# TC37XPD register map
Vendor: Infineon; Series: ATVMC; File version: 100
CPU: other r0p0, little endian, MPU, FPU, vendor SysTick, 4 interrupt priority bits
Registers are 32-bit, read-write, reset 0x0 unless marked. A register's access mark holds for its fields unless they carry their own. Offsets are from the block's base; [hi:lo] are bit positions; lines under a group give offsets from that group; {n}, {i} and the like mark numbered series.

## MTU
Base 0xF0060000
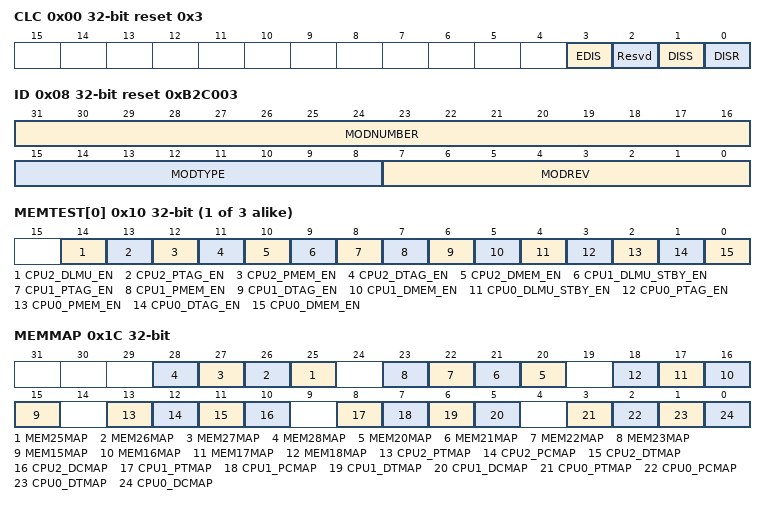
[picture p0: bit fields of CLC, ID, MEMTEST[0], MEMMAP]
0x00 CLC access per field reset 0x3 — Clock Control Register resetvalue={Application Reset:0x3}
  [3] EDIS rw — Sleep Mode Enable Control EDIS. Used for module Sleep Mode control. While any bit of tcu mbist en i x is asserted sleep mode is ignored and the MTU kernel clock runs until all tcu mbist en i x bits are deasserted.
  [2] Resvd ro — Resvd Resvd. Read as 0. Must be written with 0 H
  [1] DISS ro — Module Disable Status Bit DISS. Bit indicates the current status of the module If the RMC field is implemented and if it is 0 DISS is set automatically.
  [0] DISR rw — Module Disable Request Bit DISR. Used for enable disable control of the module. While any bit of tcu mbist en i x is asserted CLC.DISR is ignored and the MTU kernel clock runs until all tcu mbist en i x bits are deasserted.
0x08 ID ro reset 0xB2C003 — Identification Register resetvalue={Application Reset:0x0B2C003}
  [31:16] MODNUMBER — Module Number MODNUMBER. This bit field defines the module identification number. The idenfication number for the AurixPlus Platform MTU module is 00B2 H
  [15:8] MODTYPE — Module Type MODTYPE. This bit field is C0 H . It defines a 32 bit module
  [7:0] MODREV — Module Revision Number MODREV. This bit field indicates the revision number of the MTU module provided by design team .
{0x10+4i} MEMTEST[{i}] (i=0..2) — Memory MBIST Enable Register 0 resetvalue={Application Reset:0x0}
  [14] CPU2_DLMU_EN — CPU2 DLMU memory SSH instance Enable CPU2 DLMU EN
  [13] CPU2_PTAG_EN — CPU2 PTAG SSH instance Enable CPU2 PTAG EN
  [12] CPU2_PMEM_EN — CPU2 PMEM SSH instance Enable CPU2 PMEM EN
  [11] CPU2_DTAG_EN — CPU2 DTAG SSH instance Enable CPU2 DTAG EN
  [10] CPU2_DMEM_EN — CPU2 DMEM SSH instance Enable CPU2 DMEM EN
  [9] CPU1_DLMU_STBY_EN — CPU1 STANDBY DLMU SSH instance Enable CPU1 DLMU STBY EN
  [8] CPU1_PTAG_EN — CPU1 PTAG SSH instance Enable CPU1 PTAG EN
  [7] CPU1_PMEM_EN — CPU1 PMEM SSH instance Enable CPU1 PMEM EN
  [6] CPU1_DTAG_EN — CPU1 DTAG SSH instance Enable CPU1 DTAG EN
  [5] CPU1_DMEM_EN — CPU1 DMEM SSH instance Enable CPU1 DMEM EN
  [4] CPU0_DLMU_STBY_EN — CPU0 STANDBY DLMU SSH instance Enable CPU0 DLMU STBY EN
  [3] CPU0_PTAG_EN — CPU0 PTAG SSH instance Enable CPU0 PTAG EN
  [2] CPU0_PMEM_EN — CPU0 PMEM SSH instance Enable CPU0 PMEM EN
  [1] CPU0_DTAG_EN — CPU0 DTAG SSH instance Enable CPU0 DTAG EN
  [0] CPU0_DMEM_EN — CPU0 DMEM SSH instance Enable CPU0 DMEM EN
0x1C MEMMAP access per field — Memory Mapping Enable Register resetvalue={Application Reset:0x0}
  [n] MEM{n}MAP ro (n=25..28) — MEM31 Mapping Enable MEM31MAP. Reserved Not used in this product. Shall be written with zero.
  [n] MEM{n}MAP ro (n=20..23) — MEM31 Mapping Enable MEM31MAP. Reserved Not used in this product. Shall be written with zero.
  [n] MEM{n}MAP ro (n=15..18) — MEM31 Mapping Enable MEM31MAP. Reserved Not used in this product. Shall be written with zero.
  [13] CPU2_PTMAP ro — CPU2 PTAG Mapping CPU2 PTMAP. Read only. Mirrors the state of CPU2 PCMAP. CPU P cache memories may only be mapped simultaneously.
  [12] CPU2_PCMAP rw — CPU2 PCACHE Mapping CPU2 PCMAP
  [11] CPU2_DTMAP ro — CPU2 DTAG Mapping CPU2 DTMAP. Read only. Mirrors the state of CPU2 DCMAP. CPU D cache memories may only be mapped simultaneously.
  [10] CPU2_DCMAP rw — CPU2 DCache Mapping CPU2 DCMAP
  [8] CPU1_PTMAP ro — CPU1 PTAG Mapping CPU1 PTMAP. Read only. Mirrors the state of CPU1 PCMAP. CPU P cache memories may only be mapped simultaneously.
  [7] CPU1_PCMAP rw — CPU1 PCACHE Mapping CPU1 PCMAP
  [6] CPU1_DTMAP ro — CPU1 DTAG Mapping CPU1 DTMAP. Read only. Mirrors the state of CPU1 DCMAP. CPU D cache memories may only be mapped simultaneously.
  [5] CPU1_DCMAP rw — CPU1 DCache Mapping CPU1 DCMAP
  [3] CPU0_PTMAP ro — CPU0 PTAG Mapping CPU0 PTMAP. Read only. Mirrors the state of CPU0 PCMAP. CPU P cache memories may only be mapped simultaneously.
  [2] CPU0_PCMAP rw — CPU0 PCACHE Mapping CPU0 PCMAP
  [1] CPU0_DTMAP ro — CPU0 DTAG Mapping CPU0 DTMAP. Read only. Mirrors the state of CPU0 DCMAP. CPU D cache memories may only be mapped simultaneously.
  [0] CPU0_DCMAP rw — CPU0 DCache Mapping CPU0 DCMAP
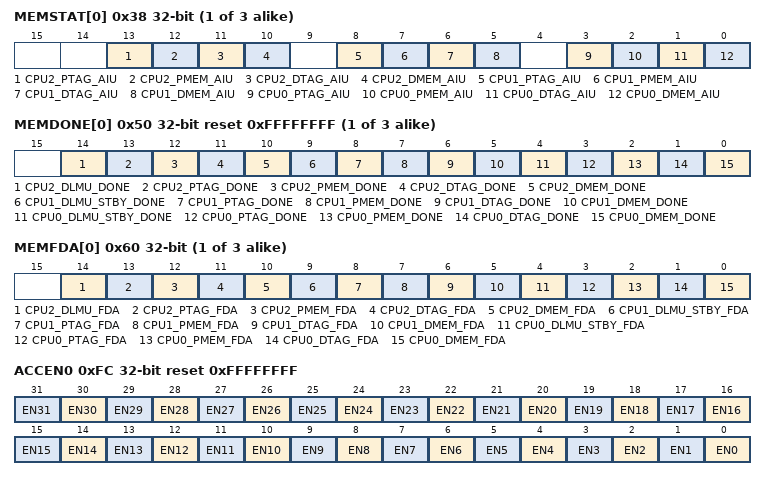
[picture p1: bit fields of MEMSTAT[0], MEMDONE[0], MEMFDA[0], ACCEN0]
{0x38+4i} MEMSTAT[{i}] (i=0..2) ro — Memory Status Register 0 resetvalue={Application Reset:0x0}
  [13] CPU2_PTAG_AIU — CPU2 PTAG MBIST AutoInitialize Underway CPU2 PTAG AIU. This bit indicates whether an automatic data initialization has been triggered by a change of state of MEMTEST.MEMxEN or MEMxMAP but that the intialization sequence has not yet completed.
  [12] CPU2_PMEM_AIU — CPU2 PMEM Partial AutoInitialize of Cache Partition Underway CPU2 PMEM AIU. This bit indicates whether an automatic data initialization has been triggered by a change of state of MEMTEST.MEMxEN or MEMxMAP but that the intialization sequence has not yet completed.
  [11] CPU2_DTAG_AIU — CPU2 DTAG MBIST AutoInitialize Underway CPU2 DTAG AIU. This bit indicates whether an automatic data initialization has been triggered by a change of state of MEMTEST.MEMxEN or MEMxMAP but that the intialization sequence has not yet completed.
  [10] CPU2_DMEM_AIU — CPU2 DMEM Partial AutoInitialize of Cache Partition Underway CPU2 DMEM AIU. This bit indicates whether an automatic data initialization has been triggered by a change of state of MEMTEST.MEMxEN or MEMxMAP but that the intialization sequence has not yet completed.
  [8] CPU1_PTAG_AIU — CPU1 PTAG MBIST AutoInitialize Underway CPU1 PTAG AIU. This bit indicates whether an automatic data initialization has been triggered by a change of state of MEMTEST.MEMxEN or MEMxMAP but that the intialization sequence has not yet completed.
  [7] CPU1_PMEM_AIU — CPU1 PMEM Partial AutoInitialize of Cache Partition Underway CPU1 PMEM AIU. This bit indicates whether an automatic data initialization has been triggered by a change of state of MEMTEST.MEMxEN or MEMxMAP but that the intialization sequence has not yet completed.
  [6] CPU1_DTAG_AIU — CPU1 DTAG MBIST AutoInitialize Underway CPU1 DTAG AIU. This bit indicates whether an automatic data initialization has been triggered by a change of state of MEMTEST.MEMxEN or MEMxMAP but that the intialization sequence has not yet completed.
  [5] CPU1_DMEM_AIU — CPU1 DMEM Partial AutoInitialize of Cache Partition Underway CPU1 DMEM AIU. This bit indicates whether an automatic data initialization has been triggered by a change of state of MEMTEST.MEMxEN or MEMxMAP but that the intialization sequence has not yet completed.
  [3] CPU0_PTAG_AIU — CPU0 PTAG MBIST AutoInitialize Underway CPU0 PTAG AIU. This bit indicates whether an automatic data initialization has been triggered by a change of state of MEMTEST.MEMxEN or MEMxMAP but that the intialization sequence has not yet completed.
  [2] CPU0_PMEM_AIU — CPU0 PMEM Partial AutoInitialize of Cache Partition Underway CPU0 PMEM AIU. This bit indicates whether an automatic data initialization has been triggered by a change of state of MEMTEST.MEMxEN or MEMxMAP but that the intialization sequence has not yet completed.
  [1] CPU0_DTAG_AIU — CPU0 DTAG MBIST AutoInitialize Underway CPU0 DTAG AIU. This bit indicates whether an automatic data initialization has been triggered by a change of state of MEMTEST.MEMxEN or MEMxMAP but that the intialization sequence has not yet completed.
  [0] CPU0_DMEM_AIU — CPU0 DMEM Partial AutoInitialize of Cache Partition Underway CPU0 DMEM AIU. This bit indicates whether an automatic data initialization has been triggered by a change of state of MEMTEST.MEMxEN or MEMxMAP but that the intialization sequence has not yet completed.
{0x50+4i} MEMDONE[{i}] (i=0..2) ro reset 0xFFFFFFFF — Memory Test Done Status Register 0 resetvalue={Application Reset:0x0FFFFFFFF}
  [14] CPU2_DLMU_DONE — CPU2 DLMU memory Test Done Status CPU2 DLMU DONE
  [13] CPU2_PTAG_DONE — CPU2 PTAG Test Done Status CPU2 PTAG DONE
  [12] CPU2_PMEM_DONE — CPU2 PMEM Test Done Status CPU2 PMEM DONE
  [11] CPU2_DTAG_DONE — CPU2 DTAG Test Done Status CPU2 DTAG DONE
  [10] CPU2_DMEM_DONE — CPU2 DMEM Test Done Status CPU2 DMEM DONE
  [9] CPU1_DLMU_STBY_DONE — CPU1 STANDBY DLMU Test Done Status CPU1 DLMU STBY DONE
  [8] CPU1_PTAG_DONE — CPU1 PTAG Test Done Status CPU1 PTAG DONE
  [7] CPU1_PMEM_DONE — CPU1 PMEM Test Done Status CPU1 PMEM DONE
  [6] CPU1_DTAG_DONE — CPU1 DTAG Test Done Status CPU1 DTAG DONE
  [5] CPU1_DMEM_DONE — CPU1 DMEM Test Done Status CPU1 DMEM DONE
  [4] CPU0_DLMU_STBY_DONE — CPU0 STANDBY DLMU Test Done Status CPU0 DLMU STBY DONE
  [3] CPU0_PTAG_DONE — CPU0 PTAG Test Done Status CPU0 PTAG DONE
  [2] CPU0_PMEM_DONE — CPU0 PMEM Test Done Status CPU0 PMEM DONE
  [1] CPU0_DTAG_DONE — CPU0 DTAG Test Done Status CPU0 DTAG DONE
  [0] CPU0_DMEM_DONE — CPU0 DMEM Test Done Status CPU0 DMEM DONE
{0x60+4i} MEMFDA[{i}] (i=0..2) ro — Memory Test FDA Status Register 0 resetvalue={Application Reset:0x0}
  [14] CPU2_DLMU_FDA — CPU2 DLMU memory Test FDA Status CPU2 DLMU FDA
  [13] CPU2_PTAG_FDA — CPU2 PTAG Test FDA Status CPU2 PTAG FDA
  [12] CPU2_PMEM_FDA — CPU2 PMEM Test FDA Status CPU2 PMEM FDA
  [11] CPU2_DTAG_FDA — CPU2 DTAG Test FDA Status CPU2 DTAG FDA
  [10] CPU2_DMEM_FDA — CPU2 DMEM Test FDA Status CPU2 DMEM FDA
  [9] CPU1_DLMU_STBY_FDA — CPU1 STANDBY DLMU Test FDA Status CPU1 DLMU STBY FDA
  [8] CPU1_PTAG_FDA — CPU1 PTAG Test FDA Status CPU1 PTAG FDA
  [7] CPU1_PMEM_FDA — CPU1 PMEM Test FDA Status CPU1 PMEM FDA
  [6] CPU1_DTAG_FDA — CPU1 DTAG Test FDA Status CPU1 DTAG FDA
  [5] CPU1_DMEM_FDA — CPU1 DMEM Test FDA Status CPU1 DMEM FDA
  [4] CPU0_DLMU_STBY_FDA — CPU0 STANDBY DLMU Test FDA Status CPU0 DLMU STBY FDA
  [3] CPU0_PTAG_FDA — CPU0 PTAG Test FDA Status CPU0 PTAG FDA
  [2] CPU0_PMEM_FDA — CPU0 PMEM Test FDA Status CPU0 PMEM FDA
  [1] CPU0_DTAG_FDA — CPU0 DTAG Test FDA Status CPU0 DTAG FDA
  [0] CPU0_DMEM_FDA — CPU0 DMEM Test FDA Status CPU0 DMEM FDA
0xFC ACCEN0 reset 0xFFFFFFFF — Access Enable Register 0 resetvalue={Application Reset:0x0FFFFFFFF}
  [n] EN{n} (n=0..31) — Access Enable for Master TAG ID 31 EN31. This bit enables write access to the MTU kernel addresses for transactions with the Master TAG ID n
{0x1000+0x100*i} MC[{i}] (i=0..95) group
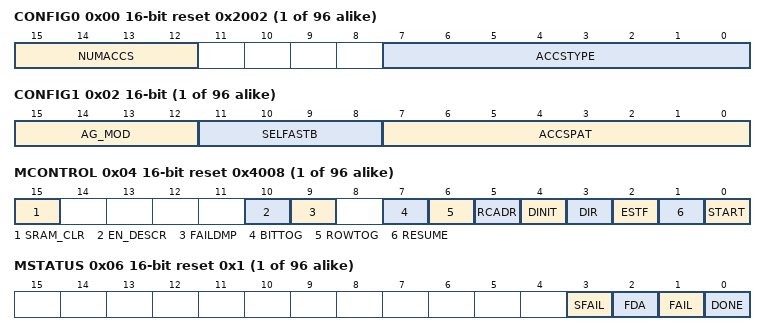
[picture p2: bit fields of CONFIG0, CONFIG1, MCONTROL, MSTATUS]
  0x00 CONFIG0 16-bit reset 0x2002 — Configuration Registers resetvalue={Application Reset:0x2002}
    [15:12] NUMACCS — Number of accesses per address NUMACCS. This field specifies the total number of accesses which are being performed to each single address in the current marching element. Allowed values 0 8 Due to size limitation of CONFIG0.ACCSTYPE and CONFIG1.ACCSPAT fields . If NUMACCS 0 will not access a memory. If NUMACCS gt 8 8 accesses will be performed.
    [7:0] ACCSTYPE — Access type ACCSTYPE. This field specifies the type of access which is being performed to each single address in the current marching element. ACCSTYPE n specifies the n th access of the marching element. 0 b write access 1 b read access
  0x02 CONFIG1 16-bit — Configuration Register 1 resetvalue={Application Reset:0x0}
    [15:12] AG_MOD — Address Generator Mode AG MOD. These bits enable the special hardware for performing the more complex addressing schemes. In case RANGE.RAEN range enable is set to 0 single access linear address mode has to be selected and NUMACCS set to 1.
    [11:8] SELFASTB — Select Fast Bit SELFASTB. This field defines during a 2 i test the address bit position that has the Hamming distance of 1 i. e. changes fastest. Bit 0 of either column or row address is swapped with the indicated bit of either column or row according to MCONTROL.RCADR. MCONTROL.RCADR 0 gt column MCONTROL.RCADR 1 gt row
    [7:0] ACCSPAT — Access pattern ACCSPAT. When AG MOD is selected for any test other than the Non Destructive test this field specifies directly the bit pattern i.e. 0 or 1 which is being used for an access to each single address in the current marching element. ACCSPAT n specifies the n th access of the marching element. These patterns are toggled according to MCONTROL.BITTOG and MCONTROL.ROWTOG. When AG MOD selects the Non Destructive test For corresponding ACCSTYPE as READ or WRITE access Program 0 when the previous read access was with normal data and 1 when the previous read was with inverted data. Note When considering the previous read access consider that the last access is a previous access to the first as a wrap around . Please refer to section on Non Destructive test for more details on how to program these bits.
  0x04 MCONTROL 16-bit reset 0x4008 — MBIST Control Register resetvalue={Application Reset:0x4008}
    [15] SRAM_CLR — Clear the SRAM SRAM CLR. This bit initializes the complete SRAM with ECC correct All 0 data. Execution is started with MCONTROL.START. For this predefined action any information contained in CONFIG0 1 RANGE registers and the bits BITTOG ROWTOG and DIR are ignored. This bit shall not be set together with other initialization or test configurations. After the SRAM clearing is complete the software has to reset this bit back to 0 before disabling the SSH. From a normal application it is forbidden to set this bit together with other initialization features. However in case it happens then this bit has lower priority than auto data init or partial erase triggered via MTU socket signals but higher priority than initialization triggered by MCONTROL.DINIT and the effect will be always that of executing the higher priority alone.
    [10] EN_DESCR — Enable Descrambling. This bit has an effect only when the SSH itself is enabled. If this bit is set the internal address de scrambler in the SSH will be enabled. That is if this bit is set the logical addresses generated from the SSH state machine and given to the SRAM input are translated to physical addresses. The reset value is 0 hence the de scrambler is not enabled by default i.e. by default the logical addresses are not translated to physical .
    [9] FAILDMP — Fail bitmap dump FAILDMP. This field enables a dump of the failing address and a fail bit map after a fault has been detected. The memory test is suspended afterwards and resumed by MCONTROL.RESUME. MSTATUS.FDA shows that a fail dump is available. This functionality can be used only if bit MCONTROL.LDRED xa0 1. In case a fail dump is available RDBFL will contain the fail bit map and ETRR the failing address.
    [7] BITTOG — Bit toggling BITTOG. This field specifies whether to toggle the used bit pattern non inverted inverted with each physical memory column. This is required when writing a checkerboard pattern or a column stripe pattern. For GALPAT this bit has to be 0.
    [6] ROWTOG — Row toggling ROWTOG. This field specifies whether to toggle the used bit pattern non inverted inverted with each physical memory row. This is required when writing a checkerboard pattern or a row stripe pattern. For GALPAT this bit has to be 0.
    [5] RCADR — Fast Row Fast Column Addressing Scheme Select RCADR. This bit selects between fast row and fast column addressing. 8220 Fast Row 8221 moves along the word lines first and then in bit line direction 8220 Fast Column 8221 along the bit lines first.
    [4] DINIT — Data Initialization Enable DINIT. This bit enables a write of the RDBFL data to all locations defined by the range register. RDBFL can contain data that will produce an ECC error. Execution is started with MCONTROL.START. For this predefined action any information contained in CONFIG0 1 registers and the bits BITTOG ROWTOG and DIR are ignored.
    [3] DIR — Direction Select DIR. This field specifies the direction of a memory test operation.
    [2] ESTF — Enable Sticky Fail Bit ESTF. This bit enables the sticky fail bit MSTATUS.SFAIL. If set any fails will be collected in MSTATUS.SFAIL. Resetting this bit to 0 will also reset MSTATUS.SFAIL.
    [1] RESUME — Resume failed test RESUME. This bit allows a test with fail that got suspended to be resumed after the dump of the fail bit map. A restart is possible only if MSTATUS.FDA was reset by hardware. It will be reset by hardware once the test is resumed.
    [0] START — START START. If this bit is written to 160 8217 1 8217 by software the memory test will start. If it is reset by software and the test has finished MSTATUS.DONE will be set to 1. If MCONTROL.FAILDMP is set a fail will stop the current execution. RESUME will continue a suspended test.
  0x06 MSTATUS 16-bit ro reset 0x1 — Status Register resetvalue={Application Reset:0x1}
    [3] SFAIL — Sticky Fail Bit SFAIL. This bit is set to 1 together with MSTATUS.FAIL provided MCONTROL.ESTF is set. In contrast to FAIL it will not be reset when a new test is started. Therefore it will collect fail information over more than one MBIST run. It will be reset when MCONTROL.ESTF is reset or MBIST mode is switched off.
    [2] FDA — Fail Dump Available FDA. This bit shows that a fail has occurred if MCONTROL.FAILDMP is set. The test is suspended and fail dump information is available. The fail bit map is in RDBFL and the associated address is in ETRR 0 . As long as no fail has occurred RDBFL contains the last read information and ETRR has no valid data . This bit will be set by hardware. It will be reset when MSTATUS was read with MSTATUS.FDA 1 and the dump information was read from ETRR and RDBFL. Only the last read from the last word of RDBFL is checked by the hardware and taken as an indication for a complete read. A suspended test will be resumed by MCONTROL.RESUME if FDA was reset. This forms some sort of handshake to insure that a suspended test can only be resumed by a broadcasted MCONTROL.RESUME if the last fail information was actually collected.
    [1] FAIL — FAIL FAIL. This bit will be reset when a test is being started. It will be set to 8216 1 8217 by hardware under the following conditions a when performing a test without redundancy MCONTROL.LDRED 8217 0 8217 and MCONTROL.USERED 8217 0 8217 FAIL 8217 1 8217 if the memory has at least one fault. Here fault includes any error in the data as well as an address error when enabled via ALMSRCS.ADDRE. In this case an application reset has to be issued to clear the FAIL bit. b when performing a test with dynamic update of redundancy MCONTROL.LDRED 8217 1 8217 and MCONTROL.USERED 8217 0 8217 FAIL 8217 1 8217 if the number of memory faults exceeds the number of redundant cells. In this case an application reset has to be performed to clear the FAIL bit. c when performing a test with pre configured redundancy MCONTROL.USERED 8217 1 8217 FAIL 8217 1 8217 if the memory or redundancy has at least one fault
    [0] DONE — DONE DONE. This bit is reset at the start of a test and set when a test is completed and MCONTROL.START was reset by software. It is not set when a test is interrupted for fail dump.
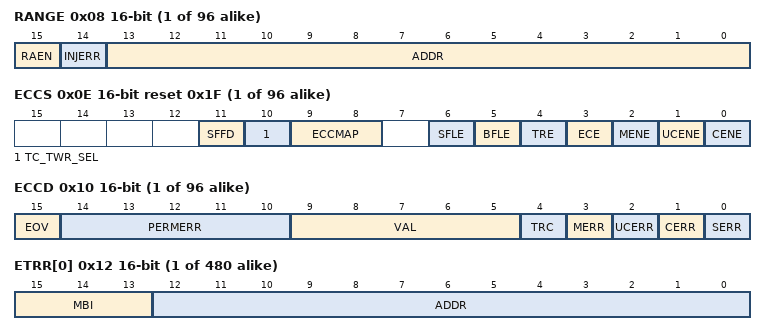
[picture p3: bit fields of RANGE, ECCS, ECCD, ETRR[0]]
  0x08 RANGE 16-bit reset not defined — Range Register single address mode resetvalue={Application Reset:0x0}
    [15] RAEN — Range Enable RAEN. 0 Disabled single address mode. In this case a single word can be addressed for read or write. Config registers have to be set as follows CONFIG.NUMACCS 8220 0001 8221 single access CONFIG.AG MOD 8220 0000 8221 linear MCONTROL.DIR 1 up For read just the value in this location will be delivered. No check against expected values is made i.e. MSTATUS.FAIL will not be set. 1 Enabled. ADDR 13 7 is interpreted as Upper Range Limit. ADDR 6 0 is interpreted as Lower Range Limit.
    [14] INJERR — Inject Error INJERR. Enables Error Injection during march tests. This is supported only for linear march tests.
    [13:0] ADDR — Address ADDR. When RAEN 0 This field specifies the address of a single memory location. Reads and writes to this location are possible. When RAEN 1 this field is interpreted as 2 different fields. ADDR 13 7 is interpreted as Upper Range Limit. ADDR 6 0 is interpreted as Lower Range Limit. For smaller SRAMs which require lesser number of address bits the MSB bits are reserved. Writes to these bits are ignored and reads return 8216 0 8217 .
  0x0C REVID 16-bit ro reset 0x610 — Revision ID Register resetvalue={Application Reset:0x610}
    [15:0] REV_ID — Revision Identifier REV ID. This field defines the currently implemented release version and functionality of the used MBIST ECC controller to track the MBIST ECC version for easier handling at the tester.
  0x0E ECCS 16-bit reset 0x1F — ECC Safety Register resetvalue={Application Reset:0x1F}
    [11] SFFD — Safety Flip Flop Diagnostics SFFD. Safety Flip Flop Diagnostics bit. Setting this bit triggers a Safety Flip Flop self test. The result of the test i.e. any error status in the safety FFs can be obtained from the OPERR or MISCERR bits in the FAULTSTS register.
    [10] TC_TWR_SEL — TriCore Tower Select TC TWR SEL. For TriCore PMEM only. This bit selects a cache way to run the non destructive inversion test on. This bit represents the Tower number.
    [9:8] ECCMAP — ECC Bit Mapping Mode ECCMAP. ECCMAP sets three different test modes to allow access to data or ECC bits separately and independently. Also memory bypass 11 mode enables a complete bypass of the whole memory. The same mode is enabled independently from the bit setting by hardware if sx ssh com lbist i input signal is set to high. All bypass modes can only be used if the memory is accessible via some bus by a processor. Otherwise these modes cannot be supported.
    [6] SFLE — Signature Bit Flip Enables SFLE. This bit injects an address error by flipping the LSB address bit to the address error detection unit but not to the SRAM. If address error detection is enabled ALMSRCS.ADDRE 1 and If this bit is set and the SRAM is read an address error is notified and tracked in the ETRR amp ERRINFO registers as well as an alarm is generated if enabled. Note that for SRAMs with Address ECC refer the Appendix chapter for the list this bit is ignored and no error will be generated.
    [5] BFLE — Bit Flip Enable BFLE
    [4] TRE — Tracking Enable TRE. All errors will be tracked if the associated notification enable bit is set. This bit is enabled by default.
    [3] ECE — Error Correction Enable ECE. This enables the single bit error correction by the ECC. If this bit is 1 single bit errors are flagged via the CE alarm. If this bit is 0 single bit errors are flagged via the UE alarm.
    [2] MENE — Miscellaneous Alarm Notification Enable MENE. This bit enables the forwarding of the ME alarm from the SSH to the SMU. Please refer to the section on safety for more details.
    [1] UCENE — Uncorrectable Error Affecting SRAM SSH Operation Alarm Notification Enable UENE. This bit enables the forwarding of the UCE alarm from the SSH to the SMU. Please refer to the section on safety for more details.
    [0] CENE — ECC Correction Event Alarm Notification Enable CENE. This bit enables the forwarding of the CE alarm from the SSH to the SMU.
  0x10 ECCD 16-bit access per field (reset mask 0x1F) — Memory ECC Detection Register resetvalue={PowerOn Reset:0x0,Application Reset:0x0}
    [15] EOV ro — Error Overflow EOV. The Error Tracking registers have an overflow condition. This bit is preserved until a warm PORST.
    [14:10] PERMERR rw — Permanent Error in ETRR Entry PERMERR. Denotes an ETRR entry that shall not be cleared by setting the TRC or moved up when a new error occurs. With this bit set the corresponding ETRR ERRINFO entry remain as they are until a PORST.
    [9:5] VAL ro — Valid Bits VAL. Every tracking register ETRRx has a valid bit associated. Reset by ECCD.TRC. 5 error tracking registers are available and 5 valid bits. These bits are preserved until a PORST.
    [4] TRC wo — Tracking Clear TRC. Writing this bit with 1 clears the EOV VAL bits plus the ETRR and ERRINFO registers depending on the PERMERR settings. This bit will always read 0.
    [3] MERR rw — Miscellaneous Error Alarm Occured MERR. Write of 8217 0 8217 clears the bit and enables further alarms to be forwarded to SMU. When the bit is set software can perform additional diagnostics from the information in the ETRR ERRINFO and ALMSRCS registers. Please refer to the safety section for more details. Write of 1 has no effect. This bit is reset with an application reset. Read as
    [2] UCERR rw — Uncorrectable Error Alarm Occured UCERR. Write of 8217 0 8217 clears the bit and enables further alarms to be forwarded to SMU. When the bit is set software can perform additional diagnostics from the information in the ETRR ERRINFO registers. Please refer to the safety section for more details. Write of 1 has no effect. This bit is cleared on an application reset. Read as
    [1] CERR rw — CE alarm occured CERR. Write of 8217 0 8217 clears the bit and enables further alarms to be forwarded to SMU. Write of 8217 1 8217 has no effect. When the bit is set software can perform additional diagnostics from the information in the ETRR ERRINFO registers. Please refer to the safety section for more details. This bit is reset with an Application Reset. Read as
    [0] SERR rw — Error Detected SERR. Write of 8217 0 8217 clears the sticky status. Write of 8217 1 8217 has no effect. In the case of a write of 8216 0 8217 simultaneously with an error detection the setting of the bit by hardware will take priority. This bit is reset with an Application Reset. Read as
  {0x12+2j} ETRR[{j}] (j=0..4) 16-bit ro — Error Tracking Register 0 resetvalue={PowerOn Reset:0x0}
    [15:13] MBI — Memory Block Index of Error i MBI. If more than one memory is implemented in parallel these three bits contain the index of the memory block in error to identify the memory in error and the tracked address belongs to this memory. Otherwise these bits always are set to 0.
    [12:0] ADDR — Address of Error i ADDR. Address of the error detected since last clear operation. If some MSB bits are not required for addressing smaller memories they are reserved and read as 8216 0 8217 .
  {0x60+2j} RDBFL[{j}] (j=0..66) 16-bit — Read Data and Bit Flip Register 0 resetvalue={Application Reset:0x0}
    [15:0] WDATA — Word Data WDATA. This field contains the data of the last memory read operation.
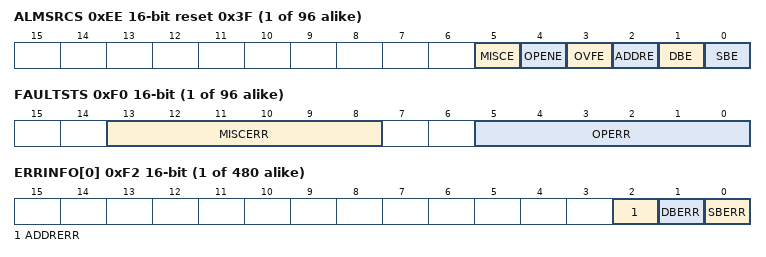
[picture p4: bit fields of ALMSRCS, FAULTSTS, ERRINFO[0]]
  0xEE ALMSRCS 16-bit reset 0x3F — Alarm Sources Configuration Register resetvalue={Application Reset:0x3F}
    [5] MISCE — SSH Misc. Errors Notification Enable MISCE. This bit enables the forwarding of many errors which may be critical to the operation of the SRAM or SSH in the future. These errors are forwarded as one of the sources of the ME alarm. The error status can be read from FAULSTS.MISCERR. This bit is enabled by default.
    [4] OPENE — SSH Operational Error Notification Enable OPENE. This bit enables the forwarding of many errors which are critical to the operation of the SRAM or SSH. These errors are forwarded as one of the sources of the UCE alarm. The error status can be read from FAULTSTS.OPERR bits. This bit is enabled by default.
    [3] OVFE — ETRR Overflow notification enable OVFE. This bit enables the forwarding of the ETRR Overflow event as an alarm source to the UCE alarm. The Error information can be obtained via the ECCD.VALID bits and the EOV bit.
    [2] ADDRE — Address Error Notification Enable ADDRE. This bit enables the detection and tracking of Address Faults in the SRAM and forward them as a source of UCE alarm. The error status can be read from the ERRINFO registers ERRINFO.ADDRERR .
    [1] DBE — Double Bit Error Notification and Tracking Enable DBE. This bit enables ECC Double Bit Errors in the SRAM to be tracked and forwarded as an UCE alarm. The error status can be read from the ERRINFO registers ERRINFO.DBERR .
    [0] SBE — Single Bit Error Notification Tracking Enable SBE. This bit enables ECC Single Bit Detection Correction event to be tracked forwarded to the CE or UCE alarm. If ECCS.ECE bit is 1 then SBE errors are forwarded to CE alarm. Otherwise to UCE alarm. The error status can be read from the ERRINFO registers ERRINFO x .SBERR
  0xF0 FAULTSTS 16-bit — SSH Safety Faults Status Register resetvalue={PowerOn Reset:0x0}
    [13:8] MISCERR — SSH Miscellaneous Error Status MISCERR. One bit status corresponding to each of the error sources contributing to the Miscellaneous Error ME alarm. Enabled by ALMSRCS.MISCE. If multiple errors happened multiple bits are set at the same time. To clear write 0 . Write of 1 has no effect. Even if any bit is set further errors are still forwarded. Unspecified bits are reserved for future use and shall always return 0.
    [5:0] OPERR — SSH Critical Operation Error Occured OPERR. One bit status corresponding to each of the error sources contributing to the Critical operational error sources to the Un Correctable Error alarm UCE . Enabled by ALMSRCS.OPENE. If multiple errors happened multiple bits are set at the same time. To clear write 0 . Write of 1 has no effect. Even if any bit is set further errors are still forwarded. Unspecified bits are reserved for future use and shall always return 0.
  {0xF2+2j} ERRINFO[{j}] (j=0..4) 16-bit ro — Error Information Register 0 resetvalue={PowerOn Reset:0x0}
    [2] ADDRERR — Address Fault Detected ADDRERR. Read as
    [1] DBERR — Double Bit Error Detected DBERR. Read as
    [0] SBERR — Single Bit Error Detected SBERR. Read as
